# ATmega1284RFR2 device description
Architecture: AVR8; Family: megaAVR
Registers are 8-bit, access not given, no defined reset value unless marked. A register's access mark holds for its fields unless they carry their own. Offsets are from the block's base; [hi:lo] are bit positions; {n}, {i} and the like mark numbered series; 'fields as' and 'values as' point back to an identical list.

## TC1 (TC16 module) — Timer/Counter, 16-bit
Instances: TC1 0x00
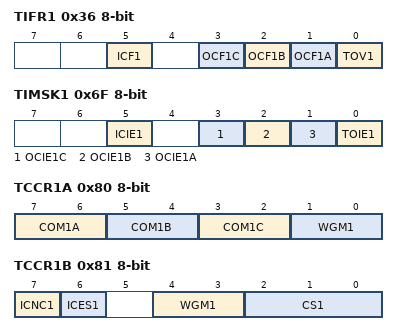
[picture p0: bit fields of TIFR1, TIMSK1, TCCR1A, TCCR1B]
0x36 TIFR1 — Timer/Counter1 Interrupt Flag Register
  [5] ICF1 — Timer/Counter1 Input Capture Flag
  [3] OCF1C — Timer/Counter1 Output Compare C Match Flag
  [2] OCF1B — Timer/Counter1 Output Compare B Match Flag
  [1] OCF1A — Timer/Counter1 Output Compare A Match Flag
  [0] TOV1 — Timer/Counter1 Overflow Flag
0x6F TIMSK1 — Timer/Counter1 Interrupt Mask Register
  [5] ICIE1 — Timer/Counter1 Input Capture Interrupt Enable
  [3] OCIE1C — Timer/Counter1 Output Compare C Match Interrupt Enable
  [2] OCIE1B — Timer/Counter1 Output Compare B Match Interrupt Enable
  [1] OCIE1A — Timer/Counter1 Output Compare A Match Interrupt Enable
  [0] TOIE1 — Timer/Counter1 Overflow Interrupt Enable
0x80 TCCR1A — Timer/Counter1 Control Register A
  [7:6] COM1A — Compare Output Mode for Channel A
    0=Normal port operation, OCnA/OCnB/OCnC disconnected; 1=Toggle OCnA/OCnB/OCnC on Compare Match; 2=Clear OCnA/OCnB/OCnC on Compare Match (set output to low level); 3=Set OCnA/OCnB/OCnC on Compare Match (set output to high level)
  [5:4] COM1B — Compare Output Mode for Channel B
    values as COM1A
  [3:2] COM1C — Compare Output Mode for Channel C
    values as COM1A
  [1:0] WGM1 — Waveform Generation Mode
    0=Normal mode of operation; 1=PWM, phase correct, 8-bit; 2=PWM, phase correct, 9-bit; 3=PWM, phase correct, 10-bit; 4=CTC, TOP = OCRnA; 5=Fast PWM, 8-bit; 6=Fast PWM, 9-bit; 7=Fast PWM, 10-bit; 8=PWM, Phase and frequency correct, TOP = ICRn; 9=PWM, Phase and frequency correct, TOP = OCRnA; 10=PWM, Phase correct, TOP = ICRn; 11=PWM, Phase correct, TOP = OCRnA; 12=CTC, TOP = OCRnA; 14=Fast PWM, TOP = ICRn; 15=Fast PWM, TOP = OCRnA
0x81 TCCR1B — Timer/Counter1 Control Register B
  [7] ICNC1 — Input Capture 1 Noise Canceller
  [6] ICES1 — Input Capture 1 Edge Select
  [4:3] WGM1 (bit 2 of the value upward) — Waveform Generation Mode
    values as TCCR1A.WGM1
  [2:0] CS1 — Clock Select
    0=No clock source (Timer/Counter stopped); 1=clk_IO/1 (no prescaling); 2=clk_IO/8 (from prescaler); 3=clk_IO/64 (from prescaler); 4=clk_IO/256 (from prescaler); 5=clk_IO/1024 (from prescaler); 6=External clock source on Tn pin, clock on falling edge; 7=External clock source on Tn pin, clock on rising edge
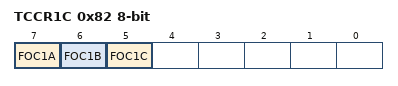
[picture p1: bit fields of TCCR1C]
0x82 TCCR1C — Timer/Counter1 Control Register C
  [7] FOC1A — Force Output Compare for Channel A
  [6] FOC1B — Force Output Compare for Channel B
  [5] FOC1C — Force Output Compare for Channel C
0x84 TCNT1 16-bit — Timer/Counter1 Bytes
0x86 ICR1 16-bit — Timer/Counter1 Input Capture Register Bytes
0x88 OCR1A 16-bit — Timer/Counter1 Output Compare Register A Bytes
0x8A OCR1B 16-bit — Timer/Counter1 Output Compare Register B Bytes
0x8C OCR1C 16-bit — Timer/Counter1 Output Compare Register C Bytes

## EEPROM
Instances: EEPROM 0x00
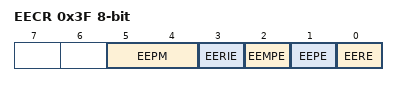
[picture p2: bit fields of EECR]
0x3F EECR — EEPROM Control Register
  [5:4] EEPM — EEPROM Programming Mode
    0=Erase and Write in one operation (Atomic Operation); 1=Erase only; 2=Write only; 3=Reserved for future use
  [3] EERIE — EEPROM Ready Interrupt Enable
  [2] EEMPE — EEPROM Master Write Enable
  [1] EEPE — EEPROM Programming Enable
  [0] EERE — EEPROM Read Enable
0x40 EEDR — EEPROM Data Register
0x41 EEAR 16-bit — EEPROM Address Register Bytes

## JTAG — JTAG Interface
Instances: JTAG 0x00
0x51 OCDR — On-Chip Debug Register
  [7:0] OCDR — On-Chip Debug Register Data
    0=Refer to the debugger documentation for further information on how to use this register
0x54 MCUSR — MCU Status Register
  [4] JTRF — JTAG Reset Flag
0x55 MCUCR — MCU Control Register
  [7] JTD — JTAG Interface Disable

## EXINT — External Interrupts
Instances: EXINT 0x00
0x3B PCIFR — Pin Change Interrupt Flag Register
  [2:0] PCIF — Pin Change Interrupt Flags
0x3C EIFR — External Interrupt Flag Register
  [7:0] INTF — External Interrupt Flag
    0=No edge or logic change on INT7:0 occurred; 1=A edge or logic change on INT0 occurred and triggered an interrupt request; 2=VAL_0x02; 128=A edge or logic change on INT7 occurred and triggered an interrupt request
0x3D EIMSK — External Interrupt Mask Register
  [7:0] INT — External Interrupt Request Enable
    0=All external pin interrupts are disabled; 255=All external pin interrupts are enabled
0x68 PCICR — Pin Change Interrupt Control Register
  [2:0] PCIE — Pin Change Interrupt Enables
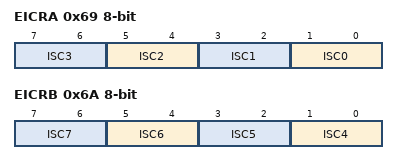
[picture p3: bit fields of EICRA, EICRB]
0x69 EICRA — External Interrupt Control Register A
  [all] fields
    0=The low level of INTn generates an interrupt request; 1=Any edge of INTn generates asynchronously an interrupt request; 2=The falling edge of INTn generates asynchronously an interrupt request; 3=The rising edge of INTn generates asynchronously an interrupt request
  [2n+1:2n] ISC{n} (n=0..3) — External Interrupt {n} Sense Control Bit
0x6A EICRB — External Interrupt Control Register B
  [all] fields
    values as the fields of EICRA
  [2n-7:2n-8] ISC{n} (n=4..7) — External Interrupt {n} Sense Control Bit
0x6B PCMSK0 — Pin Change Mask Register 0
  [7:0] PCINT — Pin Change Enable Mask
0x6C PCMSK1 — Pin Change Mask Register 1
  [7:0] PCINT (bit 8 of the value upward) — Pin Change Enable Mask
0x6D PCMSK2 — Pin Change Mask Register 2
  [7:0] PCINT (bit 16 of the value upward) — Pin Change Enable Mask
